# SAMA7G54D2G device description
Architecture: CORTEX-A7; Family: SAMA; Series: SAMA7G
Registers are 32-bit, read-write, reset 0x0 unless marked. A register's access mark holds for its fields unless they carry their own. Offsets are from the block's base; [hi:lo] are bit positions; 'fields as' and 'values as' point back to an identical list.

## MCAN_SIDFE — Standard Message ID Filter Element
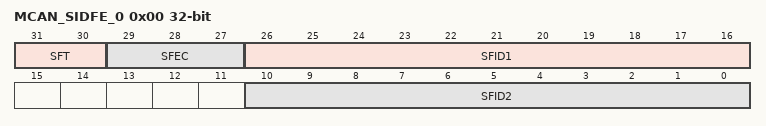
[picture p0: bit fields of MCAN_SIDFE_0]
0x00 MCAN_SIDFE_0 reset not defined — Standard Message ID Filter Element 0
  [31:30] SFT — Standard Filter Type
    0=RANGE (Range filter from SFID1 to SFID2); 1=DUAL (Dual ID filter for SF1ID or SF2ID); 2=CLASSIC (Classic filter)
  [29:27] SFEC — Standard Filter Element Configuration
    0=DISABLE (Disable filter element); 1=STF0M (Store in Rx FIFO 0 if filter matches); 2=STF1M (Store in Rx FIFO 1 if filter matches); 3=REJECT (Reject ID if filter matches); 4=PRIORITY (Set priority if filter matches); 5=PRIF0M (Set priority and store in FIFO 0 if filter matches); 6=PRIF1M (Set priority and store in FIFO 1 if filter matches); 7=STRXBUF (Store into Rx Buffer)
  [26:16] SFID1 — Standard Filter ID 1
  [10:0] SFID2 — Standard Filter ID 2

## MCAN_XIDFE — Extended Message ID Filter Element
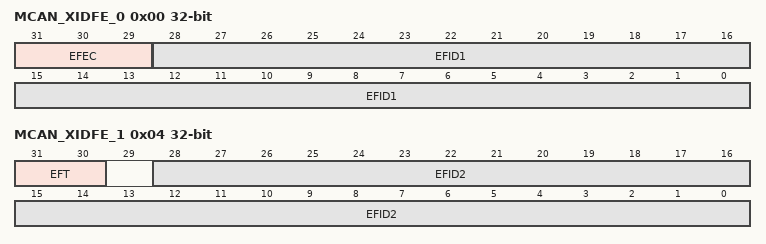
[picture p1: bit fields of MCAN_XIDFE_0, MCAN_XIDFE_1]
0x00 MCAN_XIDFE_0 reset not defined — Extended Message ID Filter Element 0
  [31:29] EFEC — Extended Filter Element Configuration
    0=DISABLE (Disable filter element); 1=STF0M (Store in Rx FIFO 0 if filter matches); 2=STF1M (Store in Rx FIFO 1 if filter matches); 3=REJECT (Reject ID if filter matches); 4=PRIORITY (Set priority if filter matches); 5=PRIF0M (Set priority and store in FIFO 0 if filter matches); 6=PRIF1M (Set priority and store in FIFO 1 if filter matches); 7=STRXBUF (Store into Rx Buffer)
  [28:0] EFID1 — Extended Filter ID 1
0x04 MCAN_XIDFE_1 reset not defined — Extended Message ID Filter Element 1
  [31:30] EFT — Extended Filter Type
    0=RANGE (Range filter from EFID1 to EFID2); 1=DUAL (Dual ID filter for EFID1 or EFID2); 2=CLASSIC (Classic filter); 3=RANGE_NO_XIDAM (Range filter from EFID1 to EFID2 with no XIDAM mask)
  [28:0] EFID2 — Extended Filter ID 2

## RSTC — Reset Controller
Instances: RSTC 0xE001D000
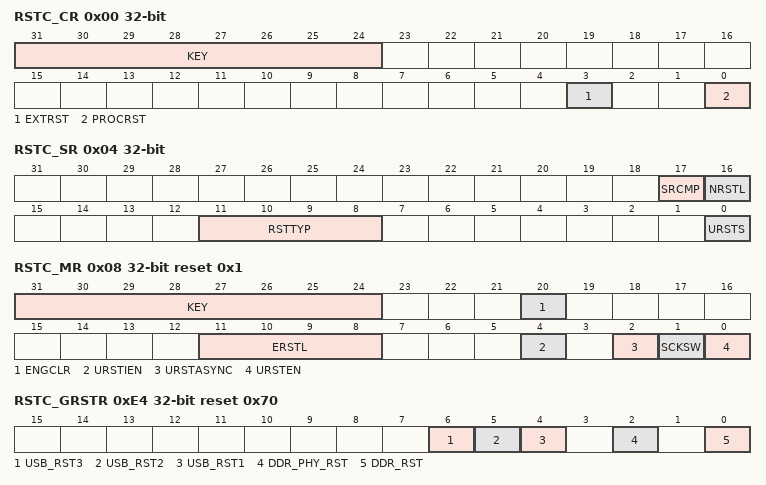
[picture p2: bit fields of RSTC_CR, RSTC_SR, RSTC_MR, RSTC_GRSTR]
0x00 RSTC_CR wo reset not defined — Control Register
  [31:24] KEY — System Reset Key
    165=PASSWD (Writing any other value in this field aborts the write operation.)
  [3] EXTRST — External Reset
    0=No effect; 1=If KEY = 0xA5, asserts the NRST_OUT pin
  [0] PROCRST — Processor Reset
    0=No effect; 1=If KEY = 0xA5, resets the processor and all the embedded peripherals
0x04 RSTC_SR ro — Status Register
  [17] SRCMP — Software Reset Command in Progress
    0=No software command is being performed by the RSTC. The RSTC is ready for a software command.; 1=A Software reset command is being performed by the RSTC. The RSTC is busy.
  [16] NRSTL — NRST Pin Level
  [11:8] RSTTYP — Reset Type
    0=GENERAL_RST (First powerup reset); 1=BACKUP_RST (Return from Backup mode); 2=WDT_RST (Watchdog fault occurred); 3=SOFT_RST (Processor reset required by the software); 4=USER_RST (NRST pin detected low); 7=SLCK_XTAL_RST (32.768 kHz crystal failure detection fault occurred); 8=ULP2_RST (ULP Mode 2 reset)
  [0] URSTS — User Reset Status
    0=No high-to-low edge on NRST happened since the last read of RSTC_SR; 1=At least one high-to-low transition of NRST has been detected since the last read of RSTC_SR
0x08 RSTC_MR reset 0x1 — Mode Register
  [31:24] KEY — Write Access Password
    165=PASSWD (Writing any other value in this field aborts the write operation. Always reads as 0.)
  [20] ENGCLR — Enable GPBR Clear on Tamper Event
    0=Disables the GPBR immediate clear on tamper detection event; 1=Enables the GPBR immediate clear on tamper detection event
  [11:8] ERSTL — External Reset Length
  [4] URSTIEN — User Reset Interrupt Enable
    0=RSTC_SR.USRTS at '1' has no effect on the RSTC interrupt line; 1=RSTC_SR.USRTS at '1' asserts the RSTC interrupt line if URSTEN = 0
  [2] URSTASYNC — User Reset Asynchronous Control
    0=The NRST input signal is managed synchronously; 1=The NRST input signal is managed asynchronously. Note: this mode cannot be selected if the external bus interface drives an SDR/DDR memory device and another memory on the same bus.
  [1] SCKSW — Slow Clock Switching
    0=The detection of a 32.768 kHz crystal failure has no effect; 1=The detection of a 32.768 kHz crystal failure resets the logic supplied by VDDCORE
  [0] URSTEN — User Reset Enable
    0=The detection of a low level on the NRST pin does not generate a User reset; 1=The detection of a low level on the NRST pin triggers a User reset
0xE4 RSTC_GRSTR reset 0x70 — Generic Reset Register
  [6] USB_RST3 — USB Reset
    0=POR_DISABLED (POR is disabled.); 1=POR_ENABLED (POR is enabled.)
  [5] USB_RST2 — USB Reset
    values as USB_RST3
  [4] USB_RST1 — USB Reset
    values as USB_RST3
  [2] DDR_PHY_RST — DDR PHY Reset
    0=DDR PHY reset is asserted; 1=DDR PHY reset is de-asserted
  [0] DDR_RST — DDR Reset
    0=DDR Controller reset is asserted; 1=DDR Controller reset is de-asserted
